CM_ "IMPORT _toyota_2017.dbc"
CM_ "IMPORT _comma.dbc"
CM_ "IMPORT _toyota_nodsu_bsm.dbc"

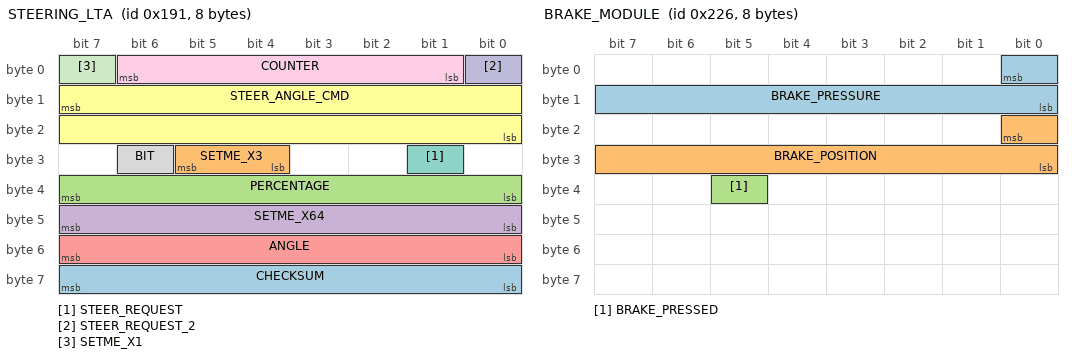
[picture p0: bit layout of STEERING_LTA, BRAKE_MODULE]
BO_ 401 STEERING_LTA: 8 XXX
 SG_ CHECKSUM : 63|8@0+ (1,0) [0|255] "" XXX
 SG_ SETME_X3 : 29|2@0+ (1,0) [0|3] "" XXX
 SG_ PERCENTAGE : 39|8@0+ (1,0) [0|255] "" XXX
 SG_ SETME_X64 : 47|8@0+ (1,0) [0|255] "" XXX
 SG_ ANGLE : 55|8@0- (0.5,0) [0|255] "" XXX
 SG_ STEER_ANGLE_CMD : 15|16@0- (0.0573,0) [-540|540] "" XXX
 SG_ STEER_REQUEST : 25|1@0+ (1,0) [0|1] "" XXX
 SG_ BIT : 30|1@0+ (1,0) [0|1] "" XXX
 SG_ COUNTER : 6|6@0+ (1,0) [0|255] "" XXX
 SG_ STEER_REQUEST_2 : 0|1@0+ (1,0) [0|1] "" XXX
 SG_ SETME_X1 : 7|1@0+ (1,0) [0|1] "" XXX

BO_ 550 BRAKE_MODULE: 8 XXX
 SG_ BRAKE_PRESSURE : 0|9@0+ (1,0) [0|511] "" XXX
 SG_ BRAKE_POSITION : 16|9@0+ (1,0) [0|511] "" XXX
 SG_ BRAKE_PRESSED : 37|1@0+ (1,0) [0|1] "" XXX

BO_ 705 GAS_PEDAL: 8 XXX
 SG_ GAS_RELEASED : 3|1@0+ (1,0) [0|1] "" XXX
 SG_ GAS_PEDAL : 55|8@0+ (0.005,0) [0|1] "" XXX

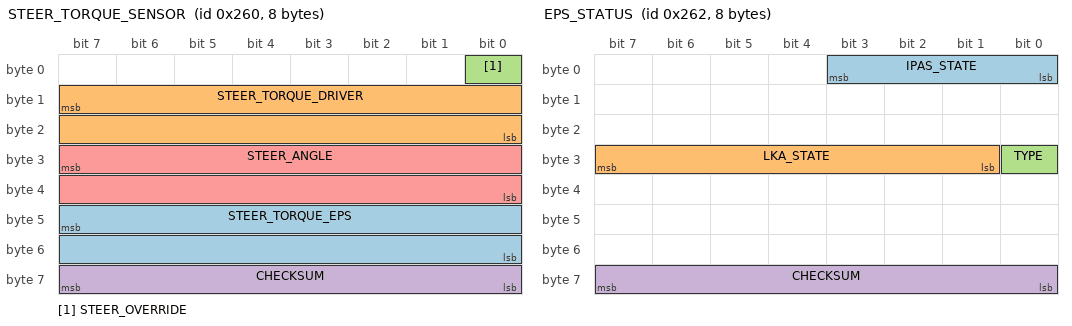
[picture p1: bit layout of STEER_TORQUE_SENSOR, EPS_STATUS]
BO_ 608 STEER_TORQUE_SENSOR: 8 XXX
 SG_ STEER_TORQUE_EPS : 47|16@0- (0.73,0) [-20000|20000] "" XXX
 SG_ STEER_TORQUE_DRIVER : 15|16@0- (1,0) [-32768|32767] "" XXX
 SG_ STEER_OVERRIDE : 0|1@0+ (1,0) [0|1] "" XXX
 SG_ CHECKSUM : 63|8@0+ (1,0) [0|255] "" XXX
 SG_ STEER_ANGLE : 31|16@0- (0.0573,0) [-500|500] "" XXX

BO_ 610 EPS_STATUS: 8 EPS
 SG_ IPAS_STATE : 3|4@0+ (1,0) [0|15] "" XXX
 SG_ LKA_STATE : 31|7@0+ (1,0) [0|127] "" XXX
 SG_ TYPE : 24|1@0+ (1,0) [0|1] "" XXX
 SG_ CHECKSUM : 63|8@0+ (1,0) [0|255] "" XXX

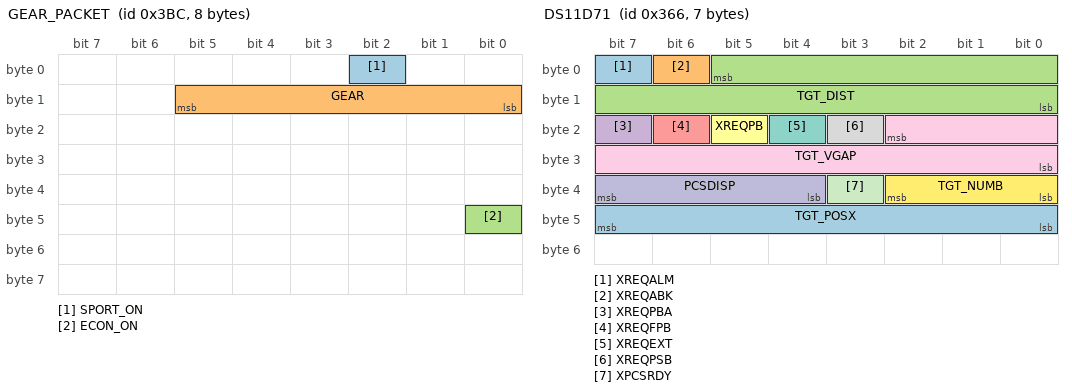
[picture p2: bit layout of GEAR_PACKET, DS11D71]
BO_ 956 GEAR_PACKET: 8 XXX
 SG_ SPORT_ON : 2|1@0+ (1,0) [0|1] "" XXX
 SG_ GEAR : 13|6@0+ (1,0) [0|63] "" XXX
 SG_ ECON_ON : 40|1@0+ (1,0) [0|1] "" XXX

BO_ 870 DS11D71: 7 DS1
 SG_ XREQALM : 7|1@0+ (1,0) [0|0] "" Vector__XXX
 SG_ XREQABK : 6|1@0+ (1,0) [0|0] "" Vector__XXX
 SG_ TGT_DIST : 5|14@0+ (0.01,0) [0|0] "m" Vector__XXX
 SG_ XREQPBA : 23|1@0+ (1,0) [0|0] "" Vector__XXX
 SG_ XREQFPB : 22|1@0+ (1,0) [0|0] "" Vector__XXX
 SG_ XREQPB : 21|1@0+ (1,0) [0|0] "" Vector__XXX
 SG_ XREQEXT : 20|1@0+ (1,0) [0|0] "" Vector__XXX
 SG_ XREQPSB : 19|1@0+ (1,0) [0|0] "" Vector__XXX
 SG_ TGT_VGAP : 18|11@0+ (0.025,-51.175) [0|0] "m/s" Vector__XXX
 SG_ PCSDISP : 39|4@0+ (1,0) [0|0] "" Vector__XXX
 SG_ XPCSRDY : 35|1@0+ (1,0) [0|0] "" Vector__XXX
 SG_ TGT_NUMB : 34|3@0+ (1,1) [0|0] "" Vector__XXX
 SG_ TGT_POSX : 47|8@0- (0.04,0) [0|0] "m" Vector__XXX

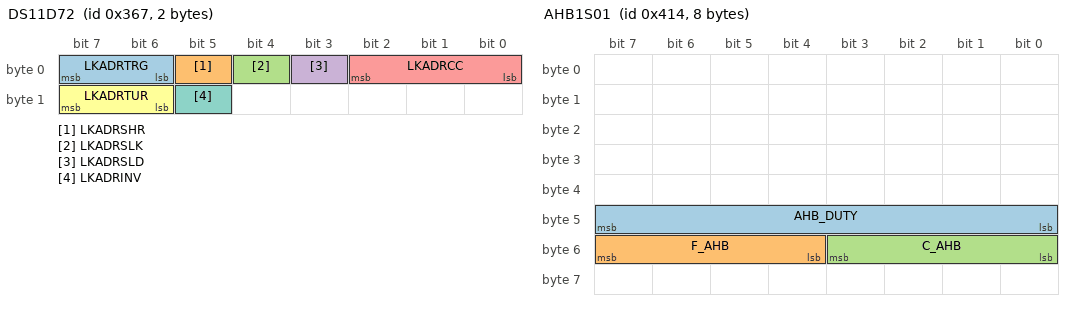
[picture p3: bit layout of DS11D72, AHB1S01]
BO_ 871 DS11D72: 2 FCM
 SG_ LKADRTRG : 7|2@0+ (1,0) [0|0] "" Vector__XXX
 SG_ LKADRSHR : 5|1@0+ (1,0) [0|0] "" Vector__XXX
 SG_ LKADRSLK : 4|1@0+ (1,0) [0|0] "" Vector__XXX
 SG_ LKADRSLD : 3|1@0+ (1,0) [0|0] "" Vector__XXX
 SG_ LKADRCC : 2|3@0+ (1,0) [0|0] "" Vector__XXX
 SG_ LKADRTUR : 15|2@0+ (1,0) [0|0] "" Vector__XXX
 SG_ LKADRINV : 13|1@0+ (1,0) [0|0] "" Vector__XXX

BO_ 1044 AHB1S01: 8 FCM
 SG_ AHB_DUTY : 47|8@0+ (0.5,0) [0|0] "%" Vector__XXX
 SG_ F_AHB : 55|4@0+ (1,0) [0|0] "" Vector__XXX
 SG_ C_AHB : 51|4@0+ (1,0) [0|0] "" Vector__XXX

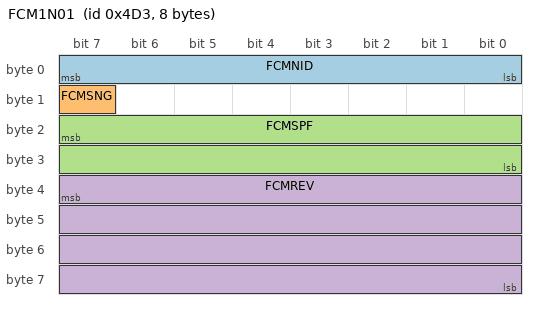
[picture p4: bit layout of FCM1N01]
BO_ 1235 FCM1N01: 8 FCM
 SG_ FCMNID : 7|8@0+ (1,0) [0|0] "" CGW
 SG_ FCMSNG : 15|1@0+ (1,0) [0|0] "" CGW
 SG_ FCMSPF : 23|16@0+ (1,0) [0|0] "" CGW
 SG_ FCMREV : 39|32@0+ (1,0) [0|0] "" CGW

CM_ SG_ 548 BRAKE_PRESSURE "seems prop to pedal force";
CM_ SG_ 548 BRAKE_POSITION "seems proportional to pedal displacement, unclear the max value of 0x1c8";
CM_ SG_ 610 TYPE "seems 1 on Corolla, 0 on all others";
VAL_ 610 IPAS_STATE 5 "override" 3 "enabled" 1 "disabled";
VAL_ 610 LKA_STATE 25 "temporary_fault" 9 "temporary_fault2" 5 "active" 1 "standby";
VAL_ 956 GEAR 0 "D" 1 "S" 8 "N" 16 "R" 32 "P";
VAL_ 956 SPORT_ON 0 "off" 1 "on";
VAL_ 956 ECON_ON 0 "off" 1 "on";
